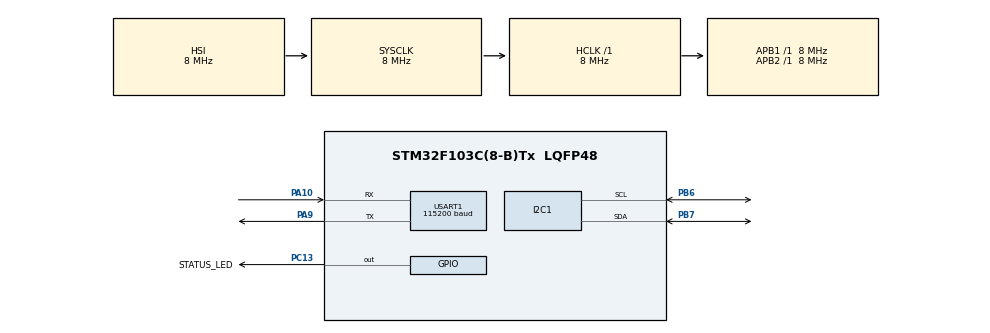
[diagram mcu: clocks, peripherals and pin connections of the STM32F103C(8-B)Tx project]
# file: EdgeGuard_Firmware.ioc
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Mcu.Family=STM32F1
Mcu.Name=STM32F103C(8-B)Tx
Mcu.Package=LQFP48
NVIC.PriorityGroup=NVIC_PRIORITYGROUP_4
PA9.Mode=Asynchronous
PA9.Signal=USART1_TX
PA10.Mode=Asynchronous
PA10.Signal=USART1_RX
PA13.Mode=Serial_Wire
PA13.Signal=SYS_JTMS-SWDIO
PA14.Mode=Serial_Wire
PA14.Signal=SYS_JTCK-SWCLK
PB6.Mode=I2C
PB6.Signal=I2C1_SCL
PB7.Mode=I2C
PB7.Signal=I2C1_SDA
PC13-TAMPER-RTC.GPIO_Label=STATUS_LED
PC13-TAMPER-RTC.PinState=GPIO_PIN_SET
PC13-TAMPER-RTC.Signal=GPIO_Output
ProjectManager.HeapSize=0x200
ProjectManager.StackSize=0x400
ProjectManager.TargetToolchain=STM32CubeIDE
RCC.SYSCLKSource=RCC_SYSCLKSOURCE_HSI
RCC.SYSCLKFreq_VALUE=8000000
RCC.AHBFreq_Value=8000000
RCC.APB1Freq_Value=8000000
RCC.APB2Freq_Value=8000000
RCC.HCLKFreq_Value=8000000
SYS.Debug=Serial_Wire
I2C1.I2C_ClockSpeed=100000
USART1.VirtualMode=VM_ASYNC
USART1.BaudRate=115200
board=custom

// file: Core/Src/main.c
/* USER CODE BEGIN Header */
/* EdgeGuard AI: STM32CubeMX/CubeIDE source layout.
 * Load EdgeGuard_Firmware.ioc in CubeMX and regenerate before first build.
 * Custom logic lives in edgeguard_app.c and survives regeneration. */
/* USER CODE END Header */
#include "main.h"
/* USER CODE BEGIN Includes */
#include "edgeguard_app.h"
/* USER CODE END Includes */
I2C_HandleTypeDef hi2c1;
UART_HandleTypeDef huart1;
void SystemClock_Config(void);
static void MX_GPIO_Init(void);
static void MX_I2C1_Init(void);
static void MX_USART1_UART_Init(void);
int main(void)
{
  HAL_Init();
  SystemClock_Config();
  MX_GPIO_Init();
  MX_I2C1_Init();
  MX_USART1_UART_Init();
  /* USER CODE BEGIN 2 */
  EdgeGuard_AppInit(&hi2c1, &huart1);
  /* USER CODE END 2 */
  /* Infinite loop */
  while (1)
  {
    /* USER CODE BEGIN 3 */
    EdgeGuard_AppTick();
  }
  /* USER CODE END 3 */
}

void SystemClock_Config(void)
{
  RCC_OscInitTypeDef RCC_OscInitStruct = {0};
  RCC_ClkInitTypeDef RCC_ClkInitStruct = {0};
  RCC_OscInitStruct.OscillatorType = RCC_OSCILLATORTYPE_HSI;
  RCC_OscInitStruct.HSIState = RCC_HSI_ON;
  RCC_OscInitStruct.HSICalibrationValue = RCC_HSICALIBRATION_DEFAULT;
  RCC_OscInitStruct.PLL.PLLState = RCC_PLL_NONE;
  if (HAL_RCC_OscConfig(&RCC_OscInitStruct) != HAL_OK) Error_Handler();
  RCC_ClkInitStruct.ClockType = RCC_CLOCKTYPE_HCLK|RCC_CLOCKTYPE_SYSCLK|
                                  RCC_CLOCKTYPE_PCLK1|RCC_CLOCKTYPE_PCLK2;
  RCC_ClkInitStruct.SYSCLKSource = RCC_SYSCLKSOURCE_HSI;
  RCC_ClkInitStruct.AHBCLKDivider = RCC_SYSCLK_DIV1;
  RCC_ClkInitStruct.APB1CLKDivider = RCC_HCLK_DIV1;
  RCC_ClkInitStruct.APB2CLKDivider = RCC_HCLK_DIV1;
  if (HAL_RCC_ClockConfig(&RCC_ClkInitStruct, FLASH_LATENCY_0) != HAL_OK)
    Error_Handler();
}

static void MX_I2C1_Init(void)
{
  hi2c1.Instance = I2C1;
  hi2c1.Init.ClockSpeed = 100000;
  hi2c1.Init.DutyCycle = I2C_DUTYCYCLE_2;
  hi2c1.Init.OwnAddress1 = 0;
  hi2c1.Init.AddressingMode = I2C_ADDRESSINGMODE_7BIT;
  hi2c1.Init.DualAddressMode = I2C_DUALADDRESS_DISABLED;
  hi2c1.Init.OwnAddress2 = 0;
  hi2c1.Init.GeneralCallMode = I2C_GENERALCALL_DISABLED;
  hi2c1.Init.NoStretchMode = I2C_NOSTRETCH_DISABLED;
  if (HAL_I2C_Init(&hi2c1) != HAL_OK) Error_Handler();
}

static void MX_USART1_UART_Init(void)
{
  huart1.Instance = USART1;
  huart1.Init.BaudRate = 115200;
  huart1.Init.WordLength = UART_WORDLENGTH_8B;
  huart1.Init.StopBits = UART_STOPBITS_1;
  huart1.Init.Parity = UART_PARITY_NONE;
  huart1.Init.Mode = UART_MODE_TX_RX;
  huart1.Init.HwFlowCtl = UART_HWCONTROL_NONE;
  huart1.Init.OverSampling = UART_OVERSAMPLING_16;
  if (HAL_UART_Init(&huart1) != HAL_OK) Error_Handler();
}

static void MX_GPIO_Init(void)
{
  GPIO_InitTypeDef GPIO_InitStruct = {0};
  __HAL_RCC_GPIOC_CLK_ENABLE();
  __HAL_RCC_GPIOA_CLK_ENABLE();
  __HAL_RCC_GPIOB_CLK_ENABLE();
  HAL_GPIO_WritePin(GPIOC, GPIO_PIN_13, GPIO_PIN_SET);
  GPIO_InitStruct.Pin = GPIO_PIN_13;
  GPIO_InitStruct.Mode = GPIO_MODE_OUTPUT_PP;
  GPIO_InitStruct.Speed = GPIO_SPEED_FREQ_LOW;
  HAL_GPIO_Init(GPIOC, &GPIO_InitStruct);
}

void Error_Handler(void)
{
  __disable_irq();
  while (1) {}
}
#ifdef USE_FULL_ASSERT
void assert_failed(uint8_t *file, uint32_t line)
{
  /* USER CODE BEGIN 6 */
  (void)file; (void)line;
  /* USER CODE END 6 */
}
#endif
